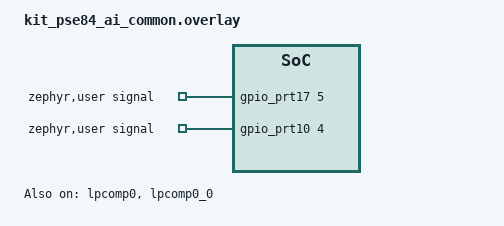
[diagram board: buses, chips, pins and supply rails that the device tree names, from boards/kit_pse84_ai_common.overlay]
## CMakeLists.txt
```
# Copyright (c) 2024 Nordic Semiconductor ASA
# SPDX-License-Identifier: Apache-2.0

cmake_minimum_required(VERSION 3.28.0)
find_package(Zephyr REQUIRED HINTS $ENV{ZEPHYR_BASE})
project(build_all_comparator)

target_sources(app PRIVATE src/main.c)
```

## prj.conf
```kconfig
# Copyright (c) 2024 Nordic Semiconductor ASA
# SPDX-License-Identifier: Apache-2.0

CONFIG_TEST=y
CONFIG_TEST_USERSPACE=y
CONFIG_COMPARATOR=y
```

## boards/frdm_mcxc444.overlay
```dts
/*
 * Copyright 2026 NXP
 *
 * SPDX-License-Identifier: Apache-2.0
 */

&cmp {
	positive-mux-input = "IN0"; /* PTC6 */
	negative-mux-input = "IN7"; /* DAC */
	dac-vref-source = "VIN2";
	dac-value = <31>;
	filter-count = <0x3>;
	filter-period = <0xf>;
	hysteresis-mode = "LEVEL2";
	enable-high-speed-mode;
	invert-output;
	enable-pin-out;
};
```

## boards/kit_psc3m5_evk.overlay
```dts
/*
 * SPDX-FileCopyrightText: Copyright (c) 2026 Infineon Technologies AG,
 * SPDX-FileCopyrightText: or an affiliate of Infineon Technologies AG. All rights reserved.
 *
 * SPDX-License-Identifier: Apache-2.0
 */

/ {
	zephyr,user {
		signal-gpios = <&gpio_prt8 3 0>, <&gpio_prt8 2 0>;
	};
};

&gpio_prt8 {
	status = "okay";
};

&lpcomp0 {
	status = "okay";
};

&lpcomp0_0 {
	output-mode = "direct";
	power = "ulp";
	intr-type = "both";
	input-p = "gpio";
	input-n = "local_vref";
	status = "disabled";
};

&lpcomp0_1 {
	output-mode = "direct";
	power = "ulp";
	intr-type = "both";
	input-p = "gpio";
	input-n = "local_vref";
	status = "okay";
};
```

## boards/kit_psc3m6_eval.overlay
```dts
/*
 * SPDX-FileCopyrightText: Copyright (c) 2026 Infineon Technologies AG,
 * SPDX-FileCopyrightText: or an affiliate of Infineon Technologies AG. All rights reserved.
 *
 * SPDX-License-Identifier: Apache-2.0
 */

&lpcomp0 {
	status = "okay";
};

&lpcomp0_1 {
	output-mode = "direct";
	power = "ulp";
	intr-type = "both";
	input-p = "gpio";
	input-n = "local_vref";
	status = "okay";
};
```

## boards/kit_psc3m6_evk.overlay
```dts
/*
 * SPDX-FileCopyrightText: Copyright (c) 2026 Infineon Technologies AG,
 * SPDX-FileCopyrightText: or an affiliate of Infineon Technologies AG. All rights reserved.
 *
 * SPDX-License-Identifier: Apache-2.0
 */

&lpcomp0 {
	status = "okay";
};

&lpcomp0_1 {
	status = "okay";
	output-mode = "direct";
	power = "ulp";
	intr-type = "both";
	input-p = "gpio";
	input-n = "local_vref";
};
```

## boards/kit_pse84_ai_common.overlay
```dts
/*
 * SPDX-FileCopyrightText: Copyright (c) 2026 Infineon Technologies AG,
 * SPDX-FileCopyrightText: or an affiliate of Infineon Technologies AG. All rights reserved.
 *
 * SPDX-License-Identifier: Apache-2.0
 */

/ {
	zephyr,user {
		signal-gpios = <&gpio_prt17 5 0>, <&gpio_prt10 4 0>;
	};
};

&gpio_prt10 {
	status = "okay";
};

&gpio_prt17 {
	status = "okay";
};

&lpcomp0 {
	status = "okay";
};

&lpcomp0_0 {
	output-mode = "direct";
	power = "ulp";
	intr-type = "both";
	input-p = "gpio";
	input-n = "local_vref";
	status = "okay";
};

&lpcomp0_1 {
	output-mode = "direct";
	power = "ulp";
	intr-type = "both";
	input-p = "gpio";
	input-n = "local_vref";
	status = "disabled";
};
```

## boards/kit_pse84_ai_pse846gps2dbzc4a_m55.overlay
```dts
/*
 * SPDX-FileCopyrightText: Copyright (c) 2026 Infineon Technologies AG,
 * SPDX-FileCopyrightText: or an affiliate of Infineon Technologies AG. All rights reserved.
 *
 * SPDX-License-Identifier: Apache-2.0
 */

#include "kit_pse84_ai_common.overlay"
```

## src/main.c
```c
/*
 * Copyright (c) 2024 Nordic Semiconductor ASA
 *
 * SPDX-License-Identifier: Apache-2.0
 */

int main(void)
{
	return 0;
}
```
